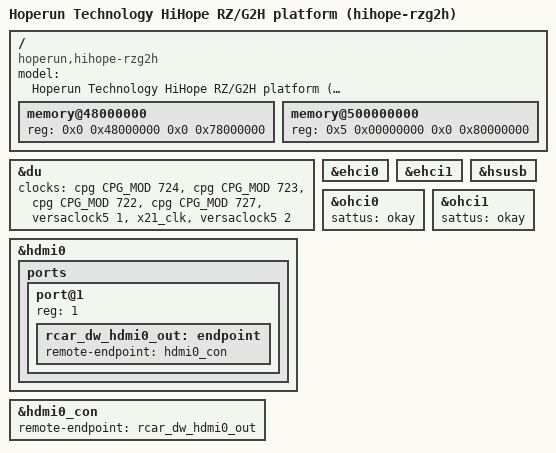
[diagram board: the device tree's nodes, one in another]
// SPDX-License-Identifier: GPL-2.0
/*
 * Device Tree Source for the HiHope RZ/G2H board
 *
 * Copyright (C) 2019 Renesas Electronics Corporation
 */

/dts-v1/;
#include "r8a774e1.dtsi"
#include "hihope-common.dtsi"

/ {
	model = "Hoperun Technology HiHope RZ/G2H platform (hihope-rzg2h)";
	compatible = "hoperun,hihope-rzg2h", "renesas,r8a774e1";

	memory@48000000 {
		device_type = "memory";
		/* first 128MB is reserved for secure area. */
		reg = <0x0 0x48000000 0x0 0x78000000>;
	};

	memory@500000000 {
		device_type = "memory";
		reg = <0x5 0x00000000 0x0 0x80000000>;
	};
};

&du {
	clocks = <&cpg CPG_MOD 724>,
		 <&cpg CPG_MOD 723>,
		 <&cpg CPG_MOD 722>,
		 <&cpg CPG_MOD 727>,
		 <&versaclock5 1>,
		 <&x21_clk>,
		 <&versaclock5 2>;
	clock-names = "du.0", "du.1", "du.2", "lvds.0",
		      "dclkin.0", "dclkin.1", "dclkin.2";
};

&hdmi0 {
	status = "okay";

	ports {
		port@1 {
			reg = <1>;
			rcar_dw_hdmi0_out: endpoint {
				remote-endpoint = <&hdmi0_con>;
			};
		};
	};
};

&hdmi0_con {
	remote-endpoint = <&rcar_dw_hdmi0_out>;
};

&ehci0 {
	status = "okay";
};

&ehci1 {
	status = "okay";
};

&hsusb {
	status = "okay";
};

&ohci0 {
	sattus = "okay";
};

&ohci1 {
	sattus = "okay";
};
